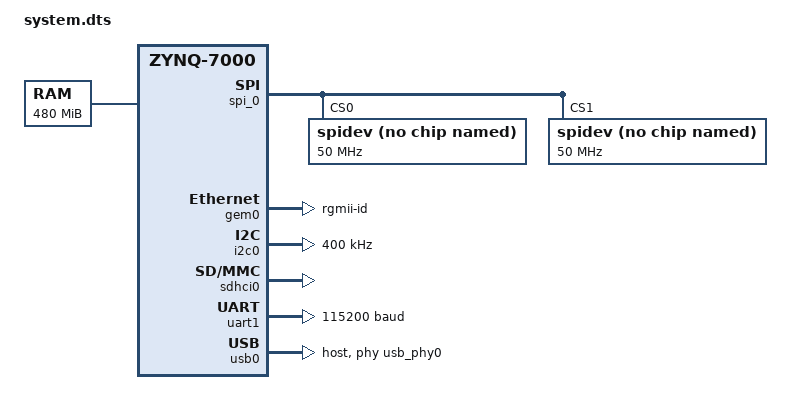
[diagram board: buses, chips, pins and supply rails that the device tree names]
/*
 * CAUTION: This file is automatically generated by Xilinx.
 * Version: HSI 2015.4
 * Today is: Fri Jun 17 04:25:35 2016
*/


/dts-v1/;
/include/ "zynq-7000.dtsi"
/ {
	cpus {
		cpu@0 {
			operating-points = <650000 1000000 325000 1000000>;
		};
	};
	chosen {
		bootargs = "console=ttyPS0,115200 root=/dev/mmcblk0p2 ro rootfstype=ext4 earlyprintk rootwait";
	};
	aliases {
		ethernet0 = &gem0;
		serial0 = &uart1;
		spi0 = &spi_0;
	};
	memory {
		device_type = "memory";
		reg = <0x0 0x1E000000>;
	};
};
&gem0 {
	local-mac-address = [00 0a 35 00 00 00];
	phy-mode = "rgmii-id";
	status = "okay";
	xlnx,ptp-enet-clock = <0x6750918>;
};
&gpio0 {
	emio-gpio-width = <64>;
	gpio-mask-high = <0x0>;
	gpio-mask-low = <0x5600>;
};
&i2c0 {
	clock-frequency = <400000>;
	status = "okay";
};
&intc {
	num_cpus = <2>;
	num_interrupts = <96>;
};
&sdhci0 {
	status = "okay";
	xlnx,has-cd = <0x0>;
	xlnx,has-power = <0x0>;
	xlnx,has-wp = <0x0>;
};
&uart1 {
	current-speed = <115200>;
	device_type = "serial";
	port-number = <0>;
	status = "okay";
};
&usb0 {
	dr_mode = "host";
	phy_type = "ulpi";
	status = "okay";
	usb-reset = <&gpio0 46 0>;
};
&clkc {
	fclk-enable = <0xf>;
	ps-clk-frequency = <50000000>;
};

/ {
    usb_phy0: phy0 {
        compatible = "ulpi-phy";
        #phy-cells = <0>;
        reg = <0xe0002000 0x1000>;
        view-port = <0x0170>;
        drv-vbus;
    };
};
&usb0 {
    usb-phy = <&usb_phy0>;
};

/ {
    amba_pl: amba_pl {
        #address-cells = <1>;
        #size-cells = <1>;
        compatible = "simple-bus";
        ranges ;
        spi_0: axi_quad_spi@40000000 {
            compatible = "xlnx,xps-spi-2.00.a";
            interrupt-parent = <&intc>;
            interrupts = <0 29 1>;
            reg = <0x40000000 0x1000>;
            xlnx,num-ss-bits = <0x2>;
        };
    };
};

&spi_0 {
	#address-cells = <1>;
	#size-cells = <0>;

	spidev@0 {
		compatible = "spidev";
		reg = <0>; // chipselect 0
		spi-max-frequency = <50000000>;
	};
	spidev@1 {
		compatible = "spidev";
		reg = <1>; // chipselect 1
		spi-max-frequency = <50000000>;
	};
};
